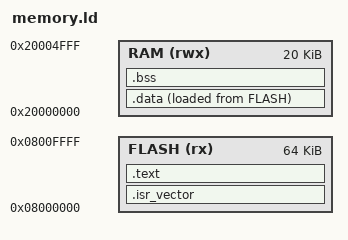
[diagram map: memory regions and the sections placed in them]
/* Linker script for STM32F103C8T6: 64 KiB Flash, 20 KiB SRAM. */
ENTRY(Reset_Handler)

MEMORY
{
    FLASH (rx)  : ORIGIN = 0x08000000, LENGTH = 64K
    RAM   (rwx) : ORIGIN = 0x20000000, LENGTH = 20K
}

_estack = ORIGIN(RAM) + LENGTH(RAM);

SECTIONS
{
    .isr_vector :
    {
        . = ALIGN(4);
        KEEP(*(.isr_vector))
        . = ALIGN(4);
    } > FLASH

    .text :
    {
        . = ALIGN(4);
        *(.text)
        *(.text*)
        *(.rodata)
        *(.rodata*)
        KEEP(*(.init))
        KEEP(*(.fini))
        . = ALIGN(4);
        _etext = .;
    } > FLASH

    _sidata = LOADADDR(.data);

    .data :
    {
        . = ALIGN(4);
        _sdata = .;
        *(.data)
        *(.data*)
        . = ALIGN(4);
        _edata = .;
    } > RAM AT > FLASH

    .bss (NOLOAD) :
    {
        . = ALIGN(4);
        _sbss = .;
        *(.bss)
        *(.bss*)
        *(COMMON)
        . = ALIGN(4);
        _ebss = .;
    } > RAM

    _flash_start = ORIGIN(FLASH);
    _flash_end   = ORIGIN(FLASH) + LENGTH(FLASH);
    _ram_start   = ORIGIN(RAM);
    _ram_end     = ORIGIN(RAM) + LENGTH(RAM);

    /DISCARD/ :
    {
        *(.comment)
        *(.note*)
    }
}
